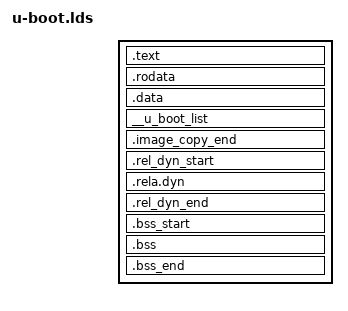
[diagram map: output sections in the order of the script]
/*
 * (C) Copyright 2013
 * David Feng <fenghua@phytium.com.cn>
 *
 * (C) Copyright 2002
 * Gary Jennejohn, DENX Software Engineering, <garyj@denx.de>
 *
 * SPDX-License-Identifier:	GPL-2.0+
 */

OUTPUT_FORMAT("elf64-littleaarch64", "elf64-littleaarch64", "elf64-littleaarch64")
OUTPUT_ARCH(aarch64)
ENTRY(_start)
SECTIONS
{
	. = 0x00000000;

	. = ALIGN(8);
	.text :
	{
		KEEP(*(.__image_copy_start));
		CPUDIR/start.o (.text*)
		*(.text*)
	}

	. = ALIGN(8);
	.rodata : { *(SORT_BY_ALIGNMENT(SORT_BY_NAME(.rodata*))) }

	. = ALIGN(8);
	.data : {
		*(.data*)
	}

	. = ALIGN(8);

	. = .;

	. = ALIGN(8);
	__u_boot_list : {
		KEEP(*(SORT(__u_boot_list*)));
	}

	. = ALIGN(8);

	.image_copy_end :
	{
		KEEP(*(.__image_copy_end));
	}

	. = ALIGN(8);

	.rel_dyn_start :
	{
		*(.__rel_dyn_start)
	}

	.rela.dyn : {
		*(.rela*)
	}

	.rel_dyn_end :
	{
		*(.__rel_dyn_end)
	}

	_end = .;

	_image_binary_end = .;

	.bss_start : {
		. = ALIGN(8);
		KEEP(*(.__bss_start));
	}

	.bss : {
		*(.bss*)
		 . = ALIGN(8);
	}

	.bss_end : {
		KEEP(*(.__bss_end));
	}

	__bss_size = __bss_end - __bss_start;

	/DISCARD/ : { *(.dynsym) }
	/DISCARD/ : { *(.dynstr*) }
	/DISCARD/ : { *(.dynamic*) }
	/DISCARD/ : { *(.plt*) }
	/DISCARD/ : { *(.interp*) }
	/DISCARD/ : { *(.gnu*) }
}
